AUTOSAR XML (schema 4-2-2)
package /Nexteer/ComponentTypes
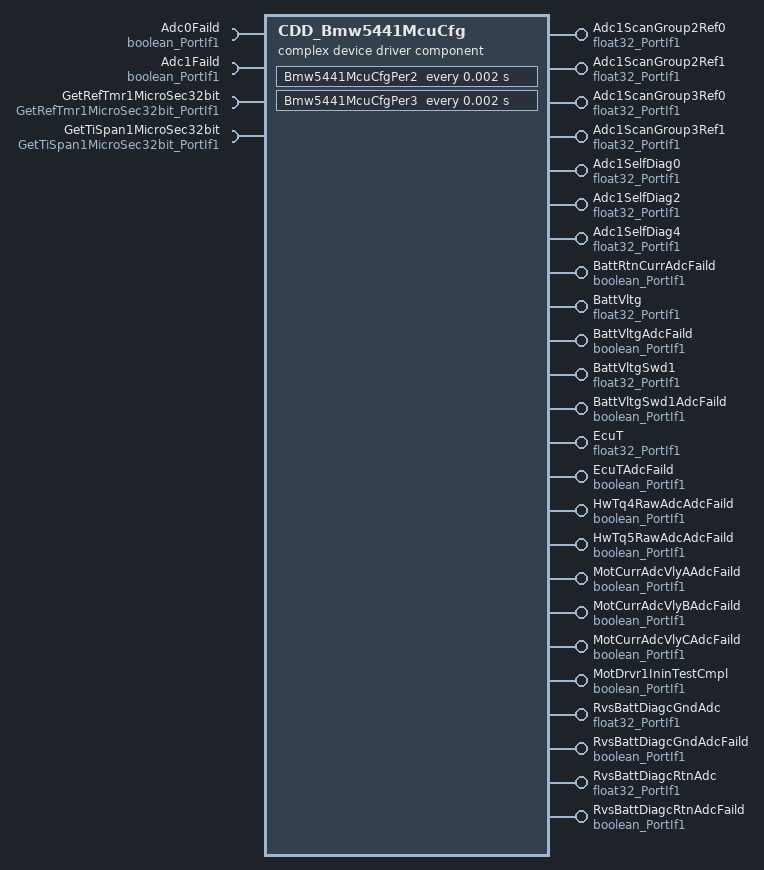
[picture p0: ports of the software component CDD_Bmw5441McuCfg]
  complex device driver sw component type CDD_Bmw5441McuCfg
    24 x provide port:
      Adc1ScanGroup2Ref0: nonqueued-sender-com-spec{data-element=Val, init-value=0}, provided-interface=float32_PortIf1
      Adc1ScanGroup2Ref1: nonqueued-sender-com-spec{data-element=Val, init-value=0}, provided-interface=float32_PortIf1
      Adc1ScanGroup3Ref0: nonqueued-sender-com-spec{data-element=Val, init-value=0}, provided-interface=float32_PortIf1
      Adc1ScanGroup3Ref1: nonqueued-sender-com-spec{data-element=Val, init-value=0}, provided-interface=float32_PortIf1
      Adc1SelfDiag0: nonqueued-sender-com-spec{data-element=Val, init-value=0}, provided-interface=float32_PortIf1
      Adc1SelfDiag2: nonqueued-sender-com-spec{data-element=Val, init-value=0}, provided-interface=float32_PortIf1
      Adc1SelfDiag4: nonqueued-sender-com-spec{data-element=Val, init-value=0}, provided-interface=float32_PortIf1
      BattRtnCurrAdcFaild: nonqueued-sender-com-spec{data-element=Logl, init-value=0}, provided-interface=boolean_PortIf1
      BattVltg: nonqueued-sender-com-spec{data-element=Val, init-value=0}, provided-interface=float32_PortIf1
      BattVltgAdcFaild: nonqueued-sender-com-spec{data-element=Logl, init-value=0}, provided-interface=boolean_PortIf1
      BattVltgSwd1: nonqueued-sender-com-spec{data-element=Val, init-value=0}, provided-interface=float32_PortIf1
      BattVltgSwd1AdcFaild: nonqueued-sender-com-spec{data-element=Logl, init-value=0}, provided-interface=boolean_PortIf1
      EcuT: nonqueued-sender-com-spec{data-element=Val, init-value=0}, provided-interface=float32_PortIf1
      EcuTAdcFaild: nonqueued-sender-com-spec{data-element=Logl, init-value=0}, provided-interface=boolean_PortIf1
      HwTq4RawAdcAdcFaild: nonqueued-sender-com-spec{data-element=Logl, init-value=0}, provided-interface=boolean_PortIf1
      HwTq5RawAdcAdcFaild: nonqueued-sender-com-spec{data-element=Logl, init-value=0}, provided-interface=boolean_PortIf1
      MotCurrAdcVlyAAdcFaild: nonqueued-sender-com-spec{data-element=Logl, init-value=0}, provided-interface=boolean_PortIf1
      MotCurrAdcVlyBAdcFaild: nonqueued-sender-com-spec{data-element=Logl, init-value=0}, provided-interface=boolean_PortIf1
      MotCurrAdcVlyCAdcFaild: nonqueued-sender-com-spec{data-element=Logl, init-value=0}, provided-interface=boolean_PortIf1
      MotDrvr1IninTestCmpl: nonqueued-sender-com-spec{data-element=Logl, init-value=0}, provided-interface=boolean_PortIf1
      RvsBattDiagcGndAdc: nonqueued-sender-com-spec{data-element=Val, init-value=0}, provided-interface=float32_PortIf1
      RvsBattDiagcGndAdcFaild: nonqueued-sender-com-spec{data-element=Logl, init-value=0}, provided-interface=boolean_PortIf1
      RvsBattDiagcRtnAdc: nonqueued-sender-com-spec{data-element=Val, init-value=0}, provided-interface=float32_PortIf1
      RvsBattDiagcRtnAdcFaild: nonqueued-sender-com-spec{data-element=Logl, init-value=0}, provided-interface=boolean_PortIf1
    4 x require port:
      Adc0Faild: nonqueued-receiver-com-spec{data-element=Logl, filter=data-filter-type=ALWAYS, init-value=0}, required-interface=boolean_PortIf1
      Adc1Faild: nonqueued-receiver-com-spec{data-element=Logl, filter=data-filter-type=ALWAYS, init-value=0}, required-interface=boolean_PortIf1
      GetRefTmr1MicroSec32bit: client-com-spec=Oper, required-interface=GetRefTmr1MicroSec32bit_PortIf1
      GetTiSpan1MicroSec32bit: client-com-spec=Oper, required-interface=GetTiSpan1MicroSec32bit_PortIf1
    behavior CDD_Bmw5441McuCfg_InternalBehavior
      init event Bmw5441McuCfgInit{1..3}_InitEvent: start-on-event=Bmw5441McuCfgInit{1..3}
      timing event TMT_Bmw5441McuCfgPer2: start-on-event=Bmw5441McuCfgPer2, period=0.002
      timing event TMT_Bmw5441McuCfgPer3: start-on-event=Bmw5441McuCfgPer3, period=0.002
      port-api-options:
        enable-take-address=false, error-handling=NO-TRANSFORMER-ERROR-HANDLING, indirect-api=false, port=Adc0Faild
        enable-take-address=false, error-handling=NO-TRANSFORMER-ERROR-HANDLING, indirect-api=false, port=Adc1Faild
        enable-take-address=false, error-handling=NO-TRANSFORMER-ERROR-HANDLING, indirect-api=false, port=Adc1ScanGroup2Ref0
        enable-take-address=false, error-handling=NO-TRANSFORMER-ERROR-HANDLING, indirect-api=false, port=Adc1ScanGroup2Ref1
        enable-take-address=false, error-handling=NO-TRANSFORMER-ERROR-HANDLING, indirect-api=false, port=Adc1ScanGroup3Ref0
        enable-take-address=false, error-handling=NO-TRANSFORMER-ERROR-HANDLING, indirect-api=false, port=Adc1ScanGroup3Ref1
        enable-take-address=false, error-handling=NO-TRANSFORMER-ERROR-HANDLING, indirect-api=false, port=Adc1SelfDiag0
        enable-take-address=false, error-handling=NO-TRANSFORMER-ERROR-HANDLING, indirect-api=false, port=Adc1SelfDiag2
        enable-take-address=false, error-handling=NO-TRANSFORMER-ERROR-HANDLING, indirect-api=false, port=Adc1SelfDiag4
        enable-take-address=false, error-handling=NO-TRANSFORMER-ERROR-HANDLING, indirect-api=false, port=BattRtnCurrAdcFaild
        enable-take-address=false, error-handling=NO-TRANSFORMER-ERROR-HANDLING, indirect-api=false, port=BattVltg
        enable-take-address=false, error-handling=NO-TRANSFORMER-ERROR-HANDLING, indirect-api=false, port=BattVltgAdcFaild
        enable-take-address=false, error-handling=NO-TRANSFORMER-ERROR-HANDLING, indirect-api=false, port=BattVltgSwd1
        enable-take-address=false, error-handling=NO-TRANSFORMER-ERROR-HANDLING, indirect-api=false, port=BattVltgSwd1AdcFaild
        enable-take-address=false, error-handling=NO-TRANSFORMER-ERROR-HANDLING, indirect-api=false, port=EcuT
        enable-take-address=false, error-handling=NO-TRANSFORMER-ERROR-HANDLING, indirect-api=false, port=EcuTAdcFaild
        enable-take-address=false, error-handling=NO-TRANSFORMER-ERROR-HANDLING, indirect-api=false, port=GetRefTmr1MicroSec32bit
        enable-take-address=false, error-handling=NO-TRANSFORMER-ERROR-HANDLING, indirect-api=false, port=GetTiSpan1MicroSec32bit
        enable-take-address=false, error-handling=NO-TRANSFORMER-ERROR-HANDLING, indirect-api=false, port=HwTq4RawAdcAdcFaild
        enable-take-address=false, error-handling=NO-TRANSFORMER-ERROR-HANDLING, indirect-api=false, port=HwTq5RawAdcAdcFaild
        enable-take-address=false, error-handling=NO-TRANSFORMER-ERROR-HANDLING, indirect-api=false, port=MotCurrAdcVlyAAdcFaild
        enable-take-address=false, error-handling=NO-TRANSFORMER-ERROR-HANDLING, indirect-api=false, port=MotCurrAdcVlyBAdcFaild
        enable-take-address=false, error-handling=NO-TRANSFORMER-ERROR-HANDLING, indirect-api=false, port=MotCurrAdcVlyCAdcFaild
        enable-take-address=false, error-handling=NO-TRANSFORMER-ERROR-HANDLING, indirect-api=false, port=MotDrvr1IninTestCmpl
        enable-take-address=false, error-handling=NO-TRANSFORMER-ERROR-HANDLING, indirect-api=false, port=RvsBattDiagcGndAdc
        enable-take-address=false, error-handling=NO-TRANSFORMER-ERROR-HANDLING, indirect-api=false, port=RvsBattDiagcGndAdcFaild
        enable-take-address=false, error-handling=NO-TRANSFORMER-ERROR-HANDLING, indirect-api=false, port=RvsBattDiagcRtnAdc
        enable-take-address=false, error-handling=NO-TRANSFORMER-ERROR-HANDLING, indirect-api=false, port=RvsBattDiagcRtnAdcFaild
      5 x runnable:
        Bmw5441McuCfgInit1
        Bmw5441McuCfgInit2
          sync call SC_GetRefTmr1MicroSec32bit_Oper: operation=GetRefTmr1MicroSec32bit.Oper, timeout=0
          sync call SC_GetTiSpan1MicroSec32bit_Oper: operation=GetTiSpan1MicroSec32bit.Oper, timeout=0
        Bmw5441McuCfgInit3
          data-send-points:
            12 x access:
              SEND_Adc1ScanGroup2Ref0_Val: accessed-variable=Adc1ScanGroup2Ref0.Val
              SEND_Adc1ScanGroup2Ref1_Val: accessed-variable=Adc1ScanGroup2Ref1.Val
              SEND_Adc1ScanGroup3Ref0_Val: accessed-variable=Adc1ScanGroup3Ref0.Val
              SEND_Adc1ScanGroup3Ref1_Val: accessed-variable=Adc1ScanGroup3Ref1.Val
              SEND_Adc1SelfDiag0_Val: accessed-variable=Adc1SelfDiag0.Val
              SEND_Adc1SelfDiag2_Val: accessed-variable=Adc1SelfDiag2.Val
              SEND_Adc1SelfDiag4_Val: accessed-variable=Adc1SelfDiag4.Val
              SEND_BattVltg_Val: accessed-variable=BattVltg.Val
              SEND_BattVltgSwd1_Val: accessed-variable=BattVltgSwd1.Val
              SEND_EcuT_Val: accessed-variable=EcuT.Val
              SEND_RvsBattDiagcGndAdc_Val: accessed-variable=RvsBattDiagcGndAdc.Val
              SEND_RvsBattDiagcRtnAdc_Val: accessed-variable=RvsBattDiagcRtnAdc.Val
        Bmw5441McuCfgPer2
          data-send-points:
            12 x access:
              SEND_Adc1ScanGroup2Ref0_Val: accessed-variable=Adc1ScanGroup2Ref0.Val
              SEND_Adc1ScanGroup2Ref1_Val: accessed-variable=Adc1ScanGroup2Ref1.Val
              SEND_Adc1ScanGroup3Ref0_Val: accessed-variable=Adc1ScanGroup3Ref0.Val
              SEND_Adc1ScanGroup3Ref1_Val: accessed-variable=Adc1ScanGroup3Ref1.Val
              SEND_Adc1SelfDiag0_Val: accessed-variable=Adc1SelfDiag0.Val
              SEND_Adc1SelfDiag2_Val: accessed-variable=Adc1SelfDiag2.Val
              SEND_Adc1SelfDiag4_Val: accessed-variable=Adc1SelfDiag4.Val
              SEND_BattVltg_Val: accessed-variable=BattVltg.Val
              SEND_BattVltgSwd1_Val: accessed-variable=BattVltgSwd1.Val
              SEND_EcuT_Val: accessed-variable=EcuT.Val
              SEND_RvsBattDiagcGndAdc_Val: accessed-variable=RvsBattDiagcGndAdc.Val
              SEND_RvsBattDiagcRtnAdc_Val: accessed-variable=RvsBattDiagcRtnAdc.Val
        Bmw5441McuCfgPer3
          data-receive-point-by-arguments:
            access REC_Adc0Faild_Logl: accessed-variable=Adc0Faild.Logl
            access REC_Adc1Faild_Logl: accessed-variable=Adc1Faild.Logl
          data-send-points:
            12 x access:
              SEND_BattRtnCurrAdcFaild_Logl: accessed-variable=BattRtnCurrAdcFaild.Logl
              SEND_BattVltgAdcFaild_Logl: accessed-variable=BattVltgAdcFaild.Logl
              SEND_BattVltgSwd1AdcFaild_Logl: accessed-variable=BattVltgSwd1AdcFaild.Logl
              SEND_EcuTAdcFaild_Logl: accessed-variable=EcuTAdcFaild.Logl
              SEND_HwTq4RawAdcAdcFaild_Logl: accessed-variable=HwTq4RawAdcAdcFaild.Logl
              SEND_HwTq5RawAdcAdcFaild_Logl: accessed-variable=HwTq5RawAdcAdcFaild.Logl
              SEND_MotCurrAdcVlyAAdcFaild_Logl: accessed-variable=MotCurrAdcVlyAAdcFaild.Logl
              SEND_MotCurrAdcVlyBAdcFaild_Logl: accessed-variable=MotCurrAdcVlyBAdcFaild.Logl
              SEND_MotCurrAdcVlyCAdcFaild_Logl: accessed-variable=MotCurrAdcVlyCAdcFaild.Logl
              SEND_MotDrvr1IninTestCmpl_Logl: accessed-variable=MotDrvr1IninTestCmpl.Logl
              SEND_RvsBattDiagcGndAdcFaild_Logl: accessed-variable=RvsBattDiagcGndAdcFaild.Logl
              SEND_RvsBattDiagcRtnAdcFaild_Logl: accessed-variable=RvsBattDiagcRtnAdcFaild.Logl
  swc implementation CDD_Bmw5441McuCfg_Implementation: behavior=CDD_Bmw5441McuCfg_InternalBehavior
    code-descriptors:
      code Default: artifact-descriptors=autosar-engineering-object={short-label=Default, category=SWSRC}
